# AT32UC3C0256C device description
Architecture: AVR32_UC3; Family: AVR UC3
Registers are 32-bit, read-write, reset 0x0 unless marked. A register's access mark holds for its fields unless they carry their own. Offsets are from the block's base; [hi:lo] are bit positions; {n}, {i} and the like mark numbered series.

## SPI — Serial Peripheral Interface
Instances: SPI0 0xfffd1800, SPI1 0xffff3400
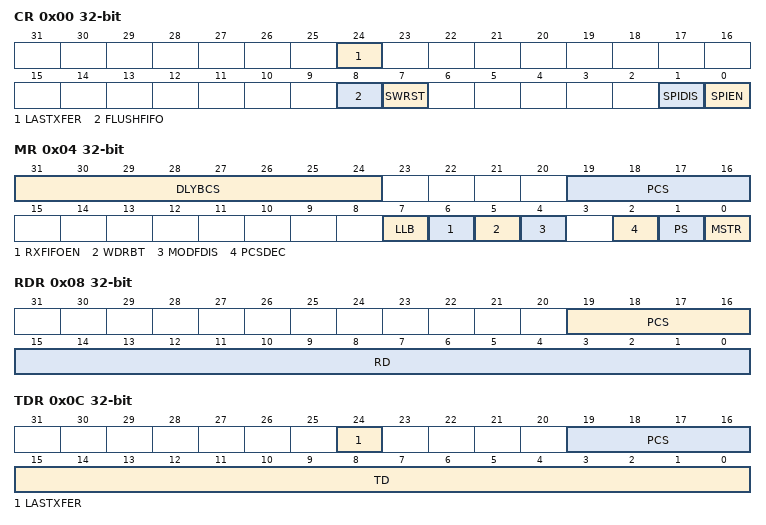
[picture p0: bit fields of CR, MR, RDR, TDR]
0x00 CR wo — Control Register
  [24] LASTXFER — Last Transfer
  [8] FLUSHFIFO — Flush FIFO command
  [7] SWRST — SPI Software Reset
  [1] SPIDIS — SPI Disable
  [0] SPIEN — SPI Enable
0x04 MR — Mode Register
  [31:24] DLYBCS — Delay Between Chip Selects
  [19:16] PCS — Peripheral Chip Select
  [7] LLB — Local Loopback Enable
  [6] RXFIFOEN — FIFO in Reception Enable
  [5] WDRBT — wait data read before transfer
  [4] MODFDIS — Mode Fault Detection
  [2] PCSDEC — Chip Select Decode
  [1] PS — Peripheral Select
  [0] MSTR — Master/Slave Mode
0x08 RDR ro — Receive Data Register
  [19:16] PCS — Peripheral Chip Select
  [15:0] RD — Receive Data
0x0C TDR wo — Transmit Data Register
  [24] LASTXFER — Last Transfer
  [19:16] PCS — Peripheral Chip Select
  [15:0] TD — Transmit Data
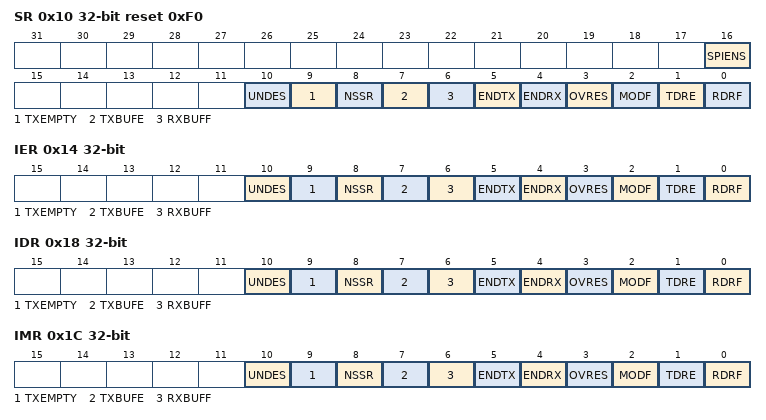
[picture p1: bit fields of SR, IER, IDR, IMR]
0x10 SR ro reset 0xF0 — Status Register
  [16] SPIENS — SPI Enable Status
  [10] UNDES — Underrun Error Status (Slave Mode Only)
  [9] TXEMPTY — Transmission Registers Empty
  [8] NSSR — NSS Rising
  [7] TXBUFE — TX Buffer Empty
  [6] RXBUFF — RX Buffer Full
  [5] ENDTX — End of TX buffer
  [4] ENDRX — End of RX buffer
  [3] OVRES — Overrun Error Status
  [2] MODF — Mode Fault Error
  [1] TDRE — Transmit Data Register Empty
  [0] RDRF — Receive Data Register Full
0x14 IER wo — Interrupt Enable Register
  [10] UNDES — Underrun Error Interrupt Enable
  [9] TXEMPTY — Transmission Registers Empty Enable
  [8] NSSR — NSS Rising Interrupt Enable
  [7] TXBUFE — Transmit Buffer Empty Interrupt Enable
  [6] RXBUFF — Receive Buffer Full Interrupt Enable
  [5] ENDTX — End of Transmit Buffer Interrupt Enable
  [4] ENDRX — End of Receive Buffer Interrupt Enable
  [3] OVRES — Overrun Error Interrupt Enable
  [2] MODF — Mode Fault Error Interrupt Enable
  [1] TDRE — Transmit Data Register Empty Interrupt Enable
  [0] RDRF — Receive Data Register Full Interrupt Enable
0x18 IDR wo — Interrupt Disable Register
  [10] UNDES — Underrun Error Interrupt Disable
  [9] TXEMPTY — Transmission Registers Empty Disable
  [8] NSSR — NSS Rising Interrupt Disable
  [7] TXBUFE — Transmit Buffer Empty Interrupt Disable
  [6] RXBUFF — Receive Buffer Full Interrupt Disable
  [5] ENDTX — End of Transmit Buffer Interrupt Disable
  [4] ENDRX — End of Receive Buffer Interrupt Disable
  [3] OVRES — Overrun Error Interrupt Disable
  [2] MODF — Mode Fault Error Interrupt Disable
  [1] TDRE — Transmit Data Register Empty Interrupt Disable
  [0] RDRF — Receive Data Register Full Interrupt Disable
0x1C IMR ro — Interrupt Mask Register
  [10] UNDES — Underrun Error Interrupt Mask
  [9] TXEMPTY — Transmission Registers Empty Mask
  [8] NSSR — NSS Rising Interrupt Mask
  [7] TXBUFE — Transmit Buffer Empty Interrupt Mask
  [6] RXBUFF — Receive Buffer Full Interrupt Mask
  [5] ENDTX — End of Transmit Buffer Interrupt Mask
  [4] ENDRX — End of Receive Buffer Interrupt Mask
  [3] OVRES — Overrun Error Interrupt Mask
  [2] MODF — Mode Fault Error Interrupt Mask
  [1] TDRE — Transmit Data Register Empty Interrupt Mask
  [0] RDRF — Receive Data Register Full Interrupt Mask
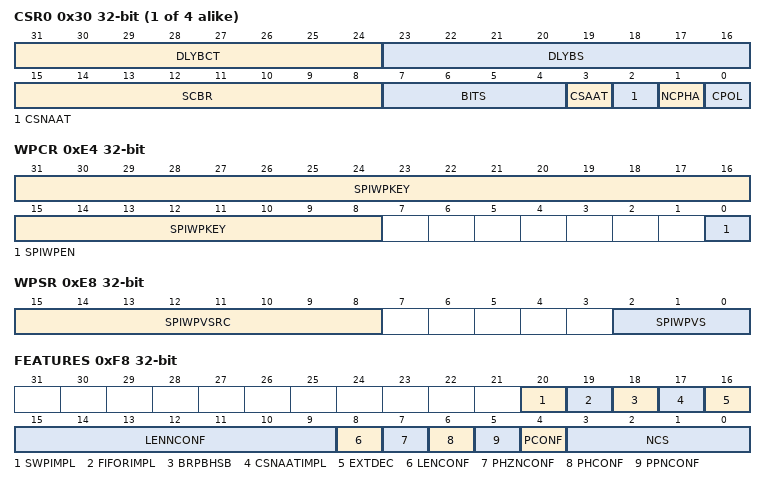
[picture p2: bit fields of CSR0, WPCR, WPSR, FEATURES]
{0x30+4i} CSR{i} (i=0..3) — Chip Select Register {i}
  [31:24] DLYBCT — Delay Between Consecutive Transfers
  [23:16] DLYBS — Delay Before SPCK
  [15:8] SCBR — Serial Clock Baud Rate
  [7:4] BITS — Bits Per Transfer
    {v}={v+8}_BPT (v=0..8)
  [3] CSAAT — Chip Select Active After Transfer
  [2] CSNAAT — Chip Select Not Active After Transfer
  [1] NCPHA — Clock Phase
  [0] CPOL — Clock Polarity
0xE4 WPCR — Write Protection control Register
  [31:8] SPIWPKEY — SPI write Protection Key Password
    0x00535049=VALUE
  [0] SPIWPEN — SPI write Protection Enable
0xE8 WPSR ro — Write Protection status Register
  [15:8] SPIWPVSRC — SPI write Protection Violation source
  [2:0] SPIWPVS — SPI write protection Violation Status
    1=WRITE_WITH_WP; 2=SWRST_WITH_WP; 4=UNEXPECTED_WRITE
0xF8 FEATURES ro reset not defined
  [20] SWPIMPL — Spurious Write Protection is Implemented
  [19] FIFORIMPL — FIFO in Reception is Implemented
  [18] BRPBHSB — Bridge Type is PB to HSB
  [17] CSNAATIMPL — CSNAAT Features are Implemented
  [16] EXTDEC — External Decoder is True
  [15:9] LENNCONF — Character Length if not Configurable
  [8] LENCONF — Character Length is Configurable
  [7] PHZNCONF — Phase is Zero if Phase is not Configurable
  [6] PHCONF — Phase is Configurable
  [5] PPNCONF — Polarity is Positive if Polarity is not Configurable
  [4] PCONF — Polarity is Configurable
  [3:0] NCS — Number of Chip Selects
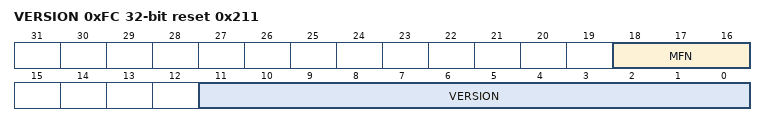
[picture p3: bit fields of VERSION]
0xFC VERSION ro reset 0x211
  [18:16] MFN, [11:0] VERSION
